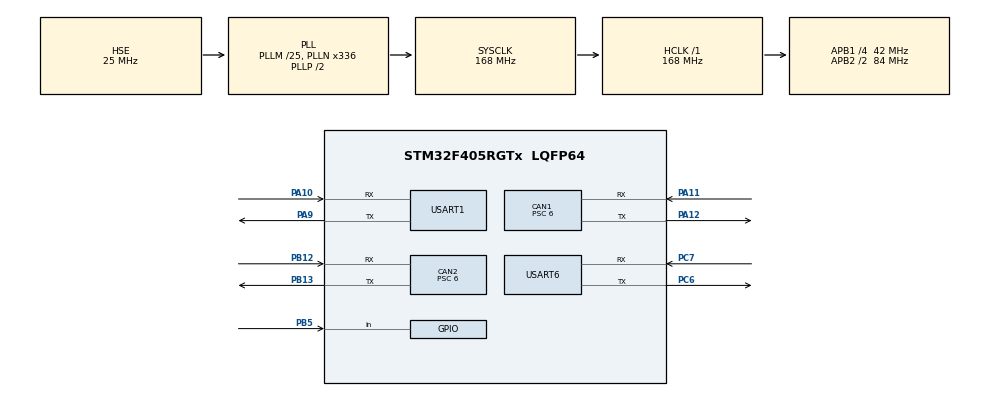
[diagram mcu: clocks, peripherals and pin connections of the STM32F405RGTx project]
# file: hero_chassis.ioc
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CAN1.ABOM=ENABLE
CAN1.AWUM=ENABLE
CAN1.BS1=CAN_BS1_4TQ
CAN1.BS2=CAN_BS2_2TQ
CAN1.CalculateBaudRate=1000000
CAN1.CalculateTimeBit=1000
CAN1.CalculateTimeQuantum=142.85714285714286
CAN1.NART=ENABLE
CAN1.Prescaler=6
CAN1.SJW=CAN_SJW_4TQ
CAN2.ABOM=ENABLE
CAN2.AWUM=ENABLE
CAN2.BS1=CAN_BS1_4TQ
CAN2.BS2=CAN_BS2_2TQ
CAN2.CalculateBaudRate=1000000
CAN2.CalculateTimeBit=1000
CAN2.CalculateTimeQuantum=142.85714285714286
CAN2.NART=ENABLE
CAN2.Prescaler=6
CAN2.SJW=CAN_SJW_4TQ
Dma.Request0=USART1_RX
Dma.USART1_RX.0.Direction=DMA_PERIPH_TO_MEMORY
Dma.USART1_RX.0.FIFOMode=DMA_FIFOMODE_DISABLE
Dma.USART1_RX.0.Instance=DMA2_Stream2
Dma.USART1_RX.0.MemDataAlignment=DMA_MDATAALIGN_BYTE
Dma.USART1_RX.0.MemInc=DMA_MINC_ENABLE
Dma.USART1_RX.0.Mode=DMA_CIRCULAR
Dma.USART1_RX.0.PeriphDataAlignment=DMA_PDATAALIGN_BYTE
Dma.USART1_RX.0.PeriphInc=DMA_PINC_DISABLE
Dma.USART1_RX.0.Priority=DMA_PRIORITY_VERY_HIGH
Mcu.Family=STM32F4
Mcu.Name=STM32F405RGTx
Mcu.Package=LQFP64
NVIC.CAN1_RX0_IRQn=true\:0\:0\:true\:false\:true\:true\:true\:true
NVIC.CAN2_RX0_IRQn=true\:0\:0\:true\:false\:true\:true\:true\:true
NVIC.DMA2_Stream2_IRQn=true\:0\:0\:false\:false\:true\:false\:true\:true
NVIC.PriorityGroup=NVIC_PRIORITYGROUP_4
NVIC.TIM6_DAC_IRQn=true\:10\:0\:true\:false\:true\:true\:true\:true
NVIC.TIM8_TRG_COM_TIM14_IRQn=true\:15\:0\:false\:false\:true\:false\:true\:true
NVIC.TimeBase=TIM8_TRG_COM_TIM14_IRQn
NVIC.TimeBaseIP=TIM14
NVIC.USART1_IRQn=true\:5\:0\:true\:false\:true\:true\:true\:true
PA10.Mode=Asynchronous
PA10.Signal=USART1_RX
PA11.Mode=CAN_Activate
PA11.Signal=CAN1_RX
PA12.Mode=CAN_Activate
PA12.Signal=CAN1_TX
PA13.Mode=Serial_Wire
PA13.Signal=SYS_JTMS-SWDIO
PA14.Mode=Serial_Wire
PA14.Signal=SYS_JTCK-SWCLK
PA9.Mode=Asynchronous
PA9.Signal=USART1_TX
PB12.Mode=CAN_Activate
PB12.Signal=CAN2_RX
PB13.Mode=CAN_Activate
PB13.Signal=CAN2_TX
PB5.GPIO_PuPd=GPIO_PULLDOWN
PB5.Signal=GPIO_Input
PC6.Mode=Asynchronous
PC6.Signal=USART6_TX
PC7.Mode=Asynchronous
PC7.Signal=USART6_RX
PH0-OSC_IN.Mode=HSE-External-Oscillator
PH0-OSC_IN.Signal=RCC_OSC_IN
PH1-OSC_OUT.Mode=HSE-External-Oscillator
PH1-OSC_OUT.Signal=RCC_OSC_OUT
ProjectManager.HeapSize=0x200
ProjectManager.StackSize=0x400
ProjectManager.TargetToolchain=MDK-ARM V5.32
RCC.48MHZClocksFreq_Value=84000000
RCC.AHBFreq_Value=168000000
RCC.APB1CLKDivider=RCC_HCLK_DIV4
RCC.APB1Freq_Value=42000000
RCC.APB1TimFreq_Value=84000000
RCC.APB2CLKDivider=RCC_HCLK_DIV2
RCC.APB2Freq_Value=84000000
RCC.APB2TimFreq_Value=168000000
RCC.CortexFreq_Value=168000000
RCC.HCLKFreq_Value=168000000
RCC.HSE_VALUE=25000000
RCC.HSI_VALUE=16000000
RCC.LSE_VALUE=32768
RCC.PLLM=25
RCC.PLLN=336
RCC.PLLSourceVirtual=RCC_PLLSOURCE_HSE
RCC.SYSCLKFreq_VALUE=168000000
RCC.SYSCLKSource=RCC_SYSCLKSOURCE_PLLCLK
RCC.VCOOutputFreq_Value=336000000
TIM6.Period=29
TIM6.Prescaler=8399
USART1.VirtualMode=VM_ASYNC
USART6.VirtualMode=VM_ASYNC
VP_SYS_VS_tim14.Mode=TIM14
VP_TIM6_VS_ClockSourceINT.Mode=Enable_Timer
board=custom

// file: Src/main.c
/* USER CODE BEGIN Header */
/**
  ******************************************************************************
  * @file           : main.c
  * @brief          : Main program body
  ******************************************************************************
  * @attention
  *
  * Copyright (c) 2023 STMicroelectronics.
  * All rights reserved.
  *
  * This software is licensed under terms that can be found in the LICENSE file
  * in the root directory of this software component.
  * If no LICENSE file comes with this software, it is provided AS-IS.
  *
  ******************************************************************************
  */
/* USER CODE END Header */
#include "main.h"
#include "can.h"
#include "dma.h"
#include "tim.h"
#include "usart.h"
#include "gpio.h"

void SystemClock_Config(void);

int main(void)
{

  /* MCU Configuration--------------------------------------------------------*/

  /* Reset of all peripherals, Initializes the Flash interface and the Systick. */
  HAL_Init();

  /* Configure the system clock */
  SystemClock_Config();

  /* Initialize all configured peripherals */
  MX_GPIO_Init();
  MX_DMA_Init();
  MX_CAN1_Init();
  MX_CAN2_Init();
  MX_USART1_UART_Init();
  MX_USART6_UART_Init();
  MX_TIM6_Init();
  /* USER CODE BEGIN 2 */
	CAN_Init();
	USART1_Init();
	TIM_Init();
	CHASSIS_INITIALIZA();
  /* USER CODE END 2 */

  /* Infinite loop */
  while (1)
  {

  }
}

void SystemClock_Config(void)
{
  RCC_OscInitTypeDef RCC_OscInitStruct = {0};
  RCC_ClkInitTypeDef RCC_ClkInitStruct = {0};

  /** Configure the main internal regulator output voltage
  */
  __HAL_RCC_PWR_CLK_ENABLE();
  __HAL_PWR_VOLTAGESCALING_CONFIG(PWR_REGULATOR_VOLTAGE_SCALE1);

  /** Initializes the RCC Oscillators according to the specified parameters
  * in the RCC_OscInitTypeDef structure.
  */
  RCC_OscInitStruct.OscillatorType = RCC_OSCILLATORTYPE_HSE;
  RCC_OscInitStruct.HSEState = RCC_HSE_ON;
  RCC_OscInitStruct.PLL.PLLState = RCC_PLL_ON;
  RCC_OscInitStruct.PLL.PLLSource = RCC_PLLSOURCE_HSE;
  RCC_OscInitStruct.PLL.PLLM = 25;
  RCC_OscInitStruct.PLL.PLLN = 336;
  RCC_OscInitStruct.PLL.PLLP = RCC_PLLP_DIV2;
  RCC_OscInitStruct.PLL.PLLQ = 4;
  if (HAL_RCC_OscConfig(&RCC_OscInitStruct) != HAL_OK)
  {
    Error_Handler();
  }

  /** Initializes the CPU, AHB and APB buses clocks
  */
  RCC_ClkInitStruct.ClockType = RCC_CLOCKTYPE_HCLK|RCC_CLOCKTYPE_SYSCLK
                              |RCC_CLOCKTYPE_PCLK1|RCC_CLOCKTYPE_PCLK2;
  RCC_ClkInitStruct.SYSCLKSource = RCC_SYSCLKSOURCE_PLLCLK;
  RCC_ClkInitStruct.AHBCLKDivider = RCC_SYSCLK_DIV1;
  RCC_ClkInitStruct.APB1CLKDivider = RCC_HCLK_DIV4;
  RCC_ClkInitStruct.APB2CLKDivider = RCC_HCLK_DIV2;

  if (HAL_RCC_ClockConfig(&RCC_ClkInitStruct, FLASH_LATENCY_5) != HAL_OK)
  {
    Error_Handler();
  }
}

void HAL_TIM_PeriodElapsedCallback(TIM_HandleTypeDef *htim)
{
  if (htim->Instance == TIM14) {
    HAL_IncTick();
  }
  /* USER CODE BEGIN Callback 1 */
  else if (htim->Instance == TIM6) {
	 	  chassis_whole();
//		  HAL_TIM_Base_Start_IT(htim);
  }
  /* USER CODE END Callback 1 */
}

void Error_Handler(void)
{
  __disable_irq();
  while (1)
  {
  }
}
